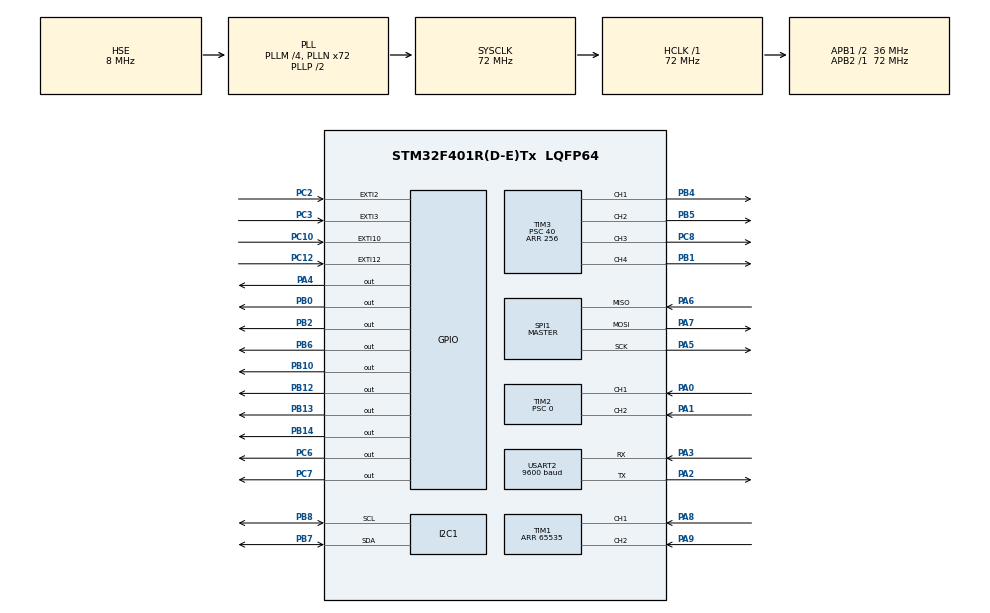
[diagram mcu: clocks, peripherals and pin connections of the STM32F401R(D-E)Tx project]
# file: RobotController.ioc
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FREERTOS.Tasks01=defaultTask,0,128,StartDefaultTask,Default,NULL
Mcu.Family=STM32F4
Mcu.Name=STM32F401R(D-E)Tx
Mcu.Package=LQFP64
NVIC.EXTI15_10_IRQn=true\:5\:0\:false\:false\:true\:true\:true\:true
NVIC.EXTI2_IRQn=true\:5\:0\:false\:false\:true\:true\:true\:true
NVIC.EXTI3_IRQn=true\:5\:0\:false\:false\:true\:true\:true\:true
NVIC.PriorityGroup=NVIC_PRIORITYGROUP_4
NVIC.TIM4_IRQn=true\:0\:0\:false\:false\:true\:false\:false\:true
NVIC.TimeBase=TIM4_IRQn
NVIC.TimeBaseIP=TIM4
PA0-WKUP.Signal=S_TIM2_CH1_ETR
PA1.Signal=S_TIM2_CH2
PA13.Mode=Serial_Wire
PA13.Signal=SYS_JTMS-SWDIO
PA14.Mode=Serial_Wire
PA14.Signal=SYS_JTCK-SWCLK
PA2.GPIO_Mode=GPIO_MODE_AF_PP
PA2.GPIO_PuPd=GPIO_PULLUP
PA2.GPIO_Speed=GPIO_SPEED_FREQ_VERY_HIGH
PA2.Mode=Asynchronous
PA2.Signal=USART2_TX
PA3.GPIO_Mode=GPIO_MODE_AF_PP
PA3.GPIO_PuPd=GPIO_PULLUP
PA3.GPIO_Speed=GPIO_SPEED_FREQ_VERY_HIGH
PA3.Mode=Asynchronous
PA3.Signal=USART2_RX
PA4.Signal=GPIO_Output
PA5.Mode=Full_Duplex_Master
PA5.Signal=SPI1_SCK
PA6.Mode=Full_Duplex_Master
PA6.Signal=SPI1_MISO
PA7.Mode=Full_Duplex_Master
PA7.Signal=SPI1_MOSI
PA8.Signal=S_TIM1_CH1
PA9.Signal=S_TIM1_CH2
PB0.Signal=GPIO_Output
PB1.Signal=S_TIM3_CH4
PB10.Signal=GPIO_Output
PB12.Signal=GPIO_Output
PB13.Signal=GPIO_Output
PB14.Signal=GPIO_Output
PB2.Signal=GPIO_Output
PB4.Signal=S_TIM3_CH1
PB5.Signal=S_TIM3_CH2
PB6.Signal=GPIO_Output
PB7.Mode=I2C
PB7.Signal=I2C1_SDA
PB8.Mode=I2C
PB8.Signal=I2C1_SCL
PC10.GPIO_ModeDefaultEXTI=GPIO_MODE_IT_RISING_FALLING
PC10.Signal=GPXTI10
PC12.GPIO_ModeDefaultEXTI=GPIO_MODE_IT_RISING_FALLING
PC12.Signal=GPXTI12
PC14-OSC32_IN.Signal=RCC_OSC32_IN
PC15-OSC32_OUT.Signal=RCC_OSC32_OUT
PC2.GPIO_ModeDefaultEXTI=GPIO_MODE_IT_RISING_FALLING
PC2.Signal=GPXTI2
PC3.GPIO_ModeDefaultEXTI=GPIO_MODE_IT_RISING_FALLING
PC3.Signal=GPXTI3
PC6.Signal=GPIO_Output
PC7.Signal=GPIO_Output
PC8.Signal=S_TIM3_CH3
PH0\ -\ OSC_IN.Mode=HSE-External-Clock-Source
PH0\ -\ OSC_IN.Signal=RCC_OSC_IN
PH1\ -\ OSC_OUT.Mode=HSE-External-Clock-Source
PH1\ -\ OSC_OUT.Signal=RCC_OSC_OUT
ProjectManager.HeapSize=0x200
ProjectManager.StackSize=0x400
ProjectManager.TargetToolchain=STM32CubeIDE
RCC.48MHZClocksFreq_Value=20571428.57142857
RCC.AHBFreq_Value=72000000
RCC.APB1CLKDivider=RCC_HCLK_DIV2
RCC.APB1Freq_Value=36000000
RCC.APB1TimFreq_Value=72000000
RCC.APB2Freq_Value=72000000
RCC.APB2TimFreq_Value=72000000
RCC.CortexFreq_Value=72000000
RCC.HCLKFreq_Value=72000000
RCC.HSE_VALUE=8000000
RCC.HSI_VALUE=16000000
RCC.LSE_VALUE=32768
RCC.PLLM=4
RCC.PLLN=72
RCC.PLLQ=7
RCC.PLLSourceVirtual=RCC_PLLSOURCE_HSE
RCC.SYSCLKFreq_VALUE=72000000
RCC.SYSCLKSource=RCC_SYSCLKSOURCE_PLLCLK
RCC.VCOOutputFreq_Value=144000000
SH.S_TIM1_CH1.0=TIM1_CH1,Encoder_Interface
SH.S_TIM1_CH2.0=TIM1_CH2,Encoder_Interface
SH.S_TIM2_CH1_ETR.0=TIM2_CH1,Encoder_Interface
SH.S_TIM2_CH2.0=TIM2_CH2,Encoder_Interface
SH.S_TIM3_CH1.0=TIM3_CH1,PWM Generation1 CH1
SH.S_TIM3_CH2.0=TIM3_CH2,PWM Generation2 CH2
SH.S_TIM3_CH3.0=TIM3_CH3,PWM Generation3 CH3
SH.S_TIM3_CH4.0=TIM3_CH4,PWM Generation4 CH4
SPI1.Direction=SPI_DIRECTION_2LINES
SPI1.Mode=SPI_MODE_MASTER
SPI1.VirtualType=VM_MASTER
TIM1.EncoderMode=TIM_ENCODERMODE_TI12
TIM1.IC2Polarity=TIM_ICPOLARITY_FALLING
TIM1.Period=65535
TIM2.EncoderMode=TIM_ENCODERMODE_TI12
TIM2.IC2Polarity=TIM_ICPOLARITY_FALLING
TIM2.Period=65535
TIM2.Prescaler=0
TIM3.Channel-PWM\ Generation1\ CH1=TIM_CHANNEL_1
TIM3.Channel-PWM\ Generation2\ CH2=TIM_CHANNEL_2
TIM3.Channel-PWM\ Generation3\ CH3=TIM_CHANNEL_3
TIM3.Channel-PWM\ Generation4\ CH4=TIM_CHANNEL_4
TIM3.Period=256
TIM3.Prescaler=40
USART2.BaudRate=9600
USART2.VirtualMode=VM_ASYNC
VP_FREERTOS_VS_CMSIS_V1.Mode=CMSIS_V1
VP_SYS_VS_tim4.Mode=TIM4
VP_TIM3_VS_ClockSourceINT.Mode=Internal
board=NUCLEO-F401RE

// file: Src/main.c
/* USER CODE BEGIN Header */
/**
  ******************************************************************************
  * @file           : main.c
  * @brief          : Main program body
  ******************************************************************************
  * @attention
  *
  * <h2><center>&copy; Copyright (c) 2019 STMicroelectronics.
  * All rights reserved.</center></h2>
  *
  * This software component is licensed by ST under BSD 3-Clause license,
  * the "License"; You may not use this file except in compliance with the
  * License. You may obtain a copy of the License at:
  *                        opensource.org/licenses/BSD-3-Clause
  *
  ******************************************************************************
  */
/* USER CODE END Header */

#include "main.h"
#include "cmsis_os.h"

I2C_HandleTypeDef hi2c1;

SPI_HandleTypeDef hspi1;

TIM_HandleTypeDef htim1;
TIM_HandleTypeDef htim2;
TIM_HandleTypeDef htim3;

UART_HandleTypeDef huart2;

osThreadId defaultTaskHandle;

void SystemClock_Config(void);
static void MX_GPIO_Init(void);
static void MX_SPI1_Init(void);
static void MX_USART2_UART_Init(void);
static void MX_TIM2_Init(void);
static void MX_TIM3_Init(void);
static void MX_I2C1_Init(void);
static void MX_TIM1_Init(void);
void StartDefaultTask(void const * argument);

int main(void)
{

  /* MCU Configuration--------------------------------------------------------*/

  /* Reset of all peripherals, Initializes the Flash interface and the Systick. */
  HAL_Init();

  /* Configure the system clock */
  SystemClock_Config();

  /* Initialize all configured peripherals */
  MX_GPIO_Init();
  MX_SPI1_Init();
  MX_USART2_UART_Init();
  MX_TIM2_Init();
  MX_TIM3_Init();
  MX_I2C1_Init();
  MX_TIM1_Init();

  /* Create the thread(s) */
  /* definition and creation of defaultTask */
  osThreadDef(defaultTask, StartDefaultTask, osPriorityNormal, 0, 128);
  defaultTaskHandle = osThreadCreate(osThread(defaultTask), NULL);

  /* USER CODE BEGIN RTOS_THREADS */
  /* add threads, ... */
  setup(&huart2, &hspi1, &htim3, &htim3, &htim2, &htim1, &hi2c1);
  /* USER CODE END RTOS_THREADS */

  /* Start scheduler */
  osKernelStart();

  /* We should never get here as control is now taken by the scheduler */

  /* Infinite loop */
  while (1)
  {

  }
}

void SystemClock_Config(void)
{
  RCC_OscInitTypeDef RCC_OscInitStruct = {0};
  RCC_ClkInitTypeDef RCC_ClkInitStruct = {0};

  /** Configure the main internal regulator output voltage
  */
  __HAL_RCC_PWR_CLK_ENABLE();
  __HAL_PWR_VOLTAGESCALING_CONFIG(PWR_REGULATOR_VOLTAGE_SCALE2);
  /** Initializes the CPU, AHB and APB busses clocks
  */
  RCC_OscInitStruct.OscillatorType = RCC_OSCILLATORTYPE_HSE;
  RCC_OscInitStruct.HSEState = RCC_HSE_BYPASS;
  RCC_OscInitStruct.PLL.PLLState = RCC_PLL_ON;
  RCC_OscInitStruct.PLL.PLLSource = RCC_PLLSOURCE_HSE;
  RCC_OscInitStruct.PLL.PLLM = 4;
  RCC_OscInitStruct.PLL.PLLN = 72;
  RCC_OscInitStruct.PLL.PLLP = RCC_PLLP_DIV2;
  RCC_OscInitStruct.PLL.PLLQ = 7;
  if (HAL_RCC_OscConfig(&RCC_OscInitStruct) != HAL_OK)
  {
    Error_Handler();
  }
  /** Initializes the CPU, AHB and APB busses clocks
  */
  RCC_ClkInitStruct.ClockType = RCC_CLOCKTYPE_HCLK|RCC_CLOCKTYPE_SYSCLK
                              |RCC_CLOCKTYPE_PCLK1|RCC_CLOCKTYPE_PCLK2;
  RCC_ClkInitStruct.SYSCLKSource = RCC_SYSCLKSOURCE_PLLCLK;
  RCC_ClkInitStruct.AHBCLKDivider = RCC_SYSCLK_DIV1;
  RCC_ClkInitStruct.APB1CLKDivider = RCC_HCLK_DIV2;
  RCC_ClkInitStruct.APB2CLKDivider = RCC_HCLK_DIV1;

  if (HAL_RCC_ClockConfig(&RCC_ClkInitStruct, FLASH_LATENCY_2) != HAL_OK)
  {
    Error_Handler();
  }
}

static void MX_I2C1_Init(void)
{

  hi2c1.Instance = I2C1;
  hi2c1.Init.ClockSpeed = 100000;
  hi2c1.Init.DutyCycle = I2C_DUTYCYCLE_2;
  hi2c1.Init.OwnAddress1 = 0;
  hi2c1.Init.AddressingMode = I2C_ADDRESSINGMODE_7BIT;
  hi2c1.Init.DualAddressMode = I2C_DUALADDRESS_DISABLE;
  hi2c1.Init.OwnAddress2 = 0;
  hi2c1.Init.GeneralCallMode = I2C_GENERALCALL_DISABLE;
  hi2c1.Init.NoStretchMode = I2C_NOSTRETCH_DISABLE;
  if (HAL_I2C_Init(&hi2c1) != HAL_OK)
  {
    Error_Handler();
  }

}

static void MX_SPI1_Init(void)
{

  /* SPI1 parameter configuration*/
  hspi1.Instance = SPI1;
  hspi1.Init.Mode = SPI_MODE_MASTER;
  hspi1.Init.Direction = SPI_DIRECTION_2LINES;
  hspi1.Init.DataSize = SPI_DATASIZE_8BIT;
  hspi1.Init.CLKPolarity = SPI_POLARITY_LOW;
  hspi1.Init.CLKPhase = SPI_PHASE_1EDGE;
  hspi1.Init.NSS = SPI_NSS_SOFT;
  hspi1.Init.BaudRatePrescaler = SPI_BAUDRATEPRESCALER_2;
  hspi1.Init.FirstBit = SPI_FIRSTBIT_MSB;
  hspi1.Init.TIMode = SPI_TIMODE_DISABLE;
  hspi1.Init.CRCCalculation = SPI_CRCCALCULATION_DISABLE;
  hspi1.Init.CRCPolynomial = 10;
  if (HAL_SPI_Init(&hspi1) != HAL_OK)
  {
    Error_Handler();
  }

}

static void MX_TIM1_Init(void)
{

  TIM_Encoder_InitTypeDef sConfig = {0};
  TIM_MasterConfigTypeDef sMasterConfig = {0};

  htim1.Instance = TIM1;
  htim1.Init.Prescaler = 0;
  htim1.Init.CounterMode = TIM_COUNTERMODE_UP;
  htim1.Init.Period = 65535;
  htim1.Init.ClockDivision = TIM_CLOCKDIVISION_DIV1;
  htim1.Init.RepetitionCounter = 0;
  htim1.Init.AutoReloadPreload = TIM_AUTORELOAD_PRELOAD_DISABLE;
  sConfig.EncoderMode = TIM_ENCODERMODE_TI12;
  sConfig.IC1Polarity = TIM_ICPOLARITY_RISING;
  sConfig.IC1Selection = TIM_ICSELECTION_DIRECTTI;
  sConfig.IC1Prescaler = TIM_ICPSC_DIV1;
  sConfig.IC1Filter = 0;
  sConfig.IC2Polarity = TIM_ICPOLARITY_FALLING;
  sConfig.IC2Selection = TIM_ICSELECTION_DIRECTTI;
  sConfig.IC2Prescaler = TIM_ICPSC_DIV1;
  sConfig.IC2Filter = 0;
  if (HAL_TIM_Encoder_Init(&htim1, &sConfig) != HAL_OK)
  {
    Error_Handler();
  }
  sMasterConfig.MasterOutputTrigger = TIM_TRGO_RESET;
  sMasterConfig.MasterSlaveMode = TIM_MASTERSLAVEMODE_DISABLE;
  if (HAL_TIMEx_MasterConfigSynchronization(&htim1, &sMasterConfig) != HAL_OK)
  {
    Error_Handler();
  }

}

static void MX_TIM2_Init(void)
{

  TIM_Encoder_InitTypeDef sConfig = {0};
  TIM_MasterConfigTypeDef sMasterConfig = {0};

  htim2.Instance = TIM2;
  htim2.Init.Prescaler = 0;
  htim2.Init.CounterMode = TIM_COUNTERMODE_UP;
  htim2.Init.Period = 65535;
  htim2.Init.ClockDivision = TIM_CLOCKDIVISION_DIV1;
  htim2.Init.AutoReloadPreload = TIM_AUTORELOAD_PRELOAD_DISABLE;
  sConfig.EncoderMode = TIM_ENCODERMODE_TI12;
  sConfig.IC1Polarity = TIM_ICPOLARITY_RISING;
  sConfig.IC1Selection = TIM_ICSELECTION_DIRECTTI;
  sConfig.IC1Prescaler = TIM_ICPSC_DIV1;
  sConfig.IC1Filter = 0;
  sConfig.IC2Polarity = TIM_ICPOLARITY_FALLING;
  sConfig.IC2Selection = TIM_ICSELECTION_DIRECTTI;
  sConfig.IC2Prescaler = TIM_ICPSC_DIV1;
  sConfig.IC2Filter = 0;
  if (HAL_TIM_Encoder_Init(&htim2, &sConfig) != HAL_OK)
  {
    Error_Handler();
  }
  sMasterConfig.MasterOutputTrigger = TIM_TRGO_RESET;
  sMasterConfig.MasterSlaveMode = TIM_MASTERSLAVEMODE_DISABLE;
  if (HAL_TIMEx_MasterConfigSynchronization(&htim2, &sMasterConfig) != HAL_OK)
  {
    Error_Handler();
  }

}

static void MX_TIM3_Init(void)
{

  TIM_ClockConfigTypeDef sClockSourceConfig = {0};
  TIM_MasterConfigTypeDef sMasterConfig = {0};
  TIM_OC_InitTypeDef sConfigOC = {0};

  htim3.Instance = TIM3;
  htim3.Init.Prescaler = 40;
  htim3.Init.CounterMode = TIM_COUNTERMODE_UP;
  htim3.Init.Period = 256;
  htim3.Init.ClockDivision = TIM_CLOCKDIVISION_DIV1;
  htim3.Init.AutoReloadPreload = TIM_AUTORELOAD_PRELOAD_DISABLE;
  if (HAL_TIM_Base_Init(&htim3) != HAL_OK)
  {
    Error_Handler();
  }
  sClockSourceConfig.ClockSource = TIM_CLOCKSOURCE_INTERNAL;
  if (HAL_TIM_ConfigClockSource(&htim3, &sClockSourceConfig) != HAL_OK)
  {
    Error_Handler();
  }
  if (HAL_TIM_PWM_Init(&htim3) != HAL_OK)
  {
    Error_Handler();
  }
  sMasterConfig.MasterOutputTrigger = TIM_TRGO_RESET;
  sMasterConfig.MasterSlaveMode = TIM_MASTERSLAVEMODE_DISABLE;
  if (HAL_TIMEx_MasterConfigSynchronization(&htim3, &sMasterConfig) != HAL_OK)
  {
    Error_Handler();
  }
  sConfigOC.OCMode = TIM_OCMODE_PWM1;
  sConfigOC.Pulse = 0;
  sConfigOC.OCPolarity = TIM_OCPOLARITY_HIGH;
  sConfigOC.OCFastMode = TIM_OCFAST_DISABLE;
  if (HAL_TIM_PWM_ConfigChannel(&htim3, &sConfigOC, TIM_CHANNEL_1) != HAL_OK)
  {
    Error_Handler();
  }
  if (HAL_TIM_PWM_ConfigChannel(&htim3, &sConfigOC, TIM_CHANNEL_2) != HAL_OK)
  {
    Error_Handler();
  }
  if (HAL_TIM_PWM_ConfigChannel(&htim3, &sConfigOC, TIM_CHANNEL_3) != HAL_OK)
  {
    Error_Handler();
  }
  if (HAL_TIM_PWM_ConfigChannel(&htim3, &sConfigOC, TIM_CHANNEL_4) != HAL_OK)
  {
    Error_Handler();
  }
  HAL_TIM_MspPostInit(&htim3);

}

static void MX_USART2_UART_Init(void)
{

  huart2.Instance = USART2;
  huart2.Init.BaudRate = 9600;
  huart2.Init.WordLength = UART_WORDLENGTH_8B;
  huart2.Init.StopBits = UART_STOPBITS_1;
  huart2.Init.Parity = UART_PARITY_NONE;
  huart2.Init.Mode = UART_MODE_TX_RX;
  huart2.Init.HwFlowCtl = UART_HWCONTROL_NONE;
  huart2.Init.OverSampling = UART_OVERSAMPLING_16;
  if (HAL_UART_Init(&huart2) != HAL_OK)
  {
    Error_Handler();
  }

}

static void MX_GPIO_Init(void)
{
  GPIO_InitTypeDef GPIO_InitStruct = {0};

  /* GPIO Ports Clock Enable */
  __HAL_RCC_GPIOC_CLK_ENABLE();
  __HAL_RCC_GPIOH_CLK_ENABLE();
  __HAL_RCC_GPIOA_CLK_ENABLE();
  __HAL_RCC_GPIOB_CLK_ENABLE();

  /*Configure GPIO pin Output Level */
  HAL_GPIO_WritePin(GPIOA, GPIO_PIN_4, GPIO_PIN_RESET);

  /*Configure GPIO pin Output Level */
  HAL_GPIO_WritePin(GPIOB, GPIO_PIN_0|GPIO_PIN_2|GPIO_PIN_10|GPIO_PIN_12
                          |GPIO_PIN_13|GPIO_PIN_14|GPIO_PIN_6, GPIO_PIN_RESET);

  /*Configure GPIO pin Output Level */
  HAL_GPIO_WritePin(GPIOC, GPIO_PIN_6|GPIO_PIN_7, GPIO_PIN_RESET);

  /*Configure GPIO pins : PC2 PC3 PC10 PC12 */
  GPIO_InitStruct.Pin = GPIO_PIN_2|GPIO_PIN_3|GPIO_PIN_10|GPIO_PIN_12;
  GPIO_InitStruct.Mode = GPIO_MODE_IT_RISING_FALLING;
  GPIO_InitStruct.Pull = GPIO_NOPULL;
  HAL_GPIO_Init(GPIOC, &GPIO_InitStruct);

  /*Configure GPIO pin : PA4 */
  GPIO_InitStruct.Pin = GPIO_PIN_4;
  GPIO_InitStruct.Mode = GPIO_MODE_OUTPUT_PP;
  GPIO_InitStruct.Pull = GPIO_NOPULL;
  GPIO_InitStruct.Speed = GPIO_SPEED_FREQ_LOW;
  HAL_GPIO_Init(GPIOA, &GPIO_InitStruct);

  /*Configure GPIO pins : PB0 PB2 PB10 PB12
                           PB13 PB14 PB6 */
  GPIO_InitStruct.Pin = GPIO_PIN_0|GPIO_PIN_2|GPIO_PIN_10|GPIO_PIN_12
                          |GPIO_PIN_13|GPIO_PIN_14|GPIO_PIN_6;
  GPIO_InitStruct.Mode = GPIO_MODE_OUTPUT_PP;
  GPIO_InitStruct.Pull = GPIO_NOPULL;
  GPIO_InitStruct.Speed = GPIO_SPEED_FREQ_LOW;
  HAL_GPIO_Init(GPIOB, &GPIO_InitStruct);

  /*Configure GPIO pins : PC6 PC7 */
  GPIO_InitStruct.Pin = GPIO_PIN_6|GPIO_PIN_7;
  GPIO_InitStruct.Mode = GPIO_MODE_OUTPUT_PP;
  GPIO_InitStruct.Pull = GPIO_NOPULL;
  GPIO_InitStruct.Speed = GPIO_SPEED_FREQ_LOW;
  HAL_GPIO_Init(GPIOC, &GPIO_InitStruct);

  /* EXTI interrupt init*/
  HAL_NVIC_SetPriority(EXTI2_IRQn, 5, 0);
  HAL_NVIC_EnableIRQ(EXTI2_IRQn);

  HAL_NVIC_SetPriority(EXTI3_IRQn, 5, 0);
  HAL_NVIC_EnableIRQ(EXTI3_IRQn);

  HAL_NVIC_SetPriority(EXTI15_10_IRQn, 5, 0);
  HAL_NVIC_EnableIRQ(EXTI15_10_IRQn);

}

void StartDefaultTask(void const * argument)
{

  /* USER CODE BEGIN 5 */
//    const char wmsg[] = "Some data";
//    char rmsg[sizeof(wmsg)];
//    // HAL expects address to be shifted one bit to the left
//    uint16_t devAddr = (0x50 << 1);
//    uint16_t memAddr = 0x0100;
//    HAL_StatusTypeDef status;
//    char xBuffer[1];
//    // Hint: try to comment this line
////    status = HAL_I2C_Mem_Write(&hi2c1, devAddr, memAddr, I2C_MEMADD_SIZE_16BIT,
////        (uint8_t*)wmsg, sizeof(wmsg), HAL_MAX_DELAY);
////
////    for(;;) { // wait...
////        status = HAL_I2C_IsDeviceReady(&hi2c1, devAddr, 1,
////                                       HAL_MAX_DELAY);
////        if(status == HAL_OK)
////            break;
////    }
//
//    status = HAL_I2C_Mem_Read(&hi2c1, devAddr, memAddr+1, I2C_MEMADD_SIZE_16BIT,
//    		(uint8_t*)xBuffer, 1, HAL_MAX_DELAY);
//
////    status = HAL_I2C_Mem_Read(&hi2c1, devAddr, memAddr, I2C_MEMADD_SIZE_16BIT,
////        (uint8_t*)rmsg, sizeof(rmsg), HAL_MAX_DELAY);
//
//
////    if(memcmp(rmsg, wmsg, sizeof(rmsg)) == 0) {
////        const char result[] = "Test passed!\r\n";
////        HAL_UART_Transmit(&huart2, (uint8_t*)result, sizeof(result)-1,
////                          HAL_MAX_DELAY);
////    } else {
////        const char result[] = "Test failed :(\r\n";
////        HAL_UART_Transmit(&huart2, (uint8_t*)result, sizeof(result)-1,
////                          HAL_MAX_DELAY);
////    }
    for(;;){
    	osDelay(5);
    }
  /* USER CODE END 5 */
}

void HAL_TIM_PeriodElapsedCallback(TIM_HandleTypeDef *htim)
{
  if (htim->Instance == TIM4) {
    HAL_IncTick();
  }
}

void Error_Handler(void)
{
}

/************************ (C) COPYRIGHT STMicroelectronics *****END OF FILE****/
